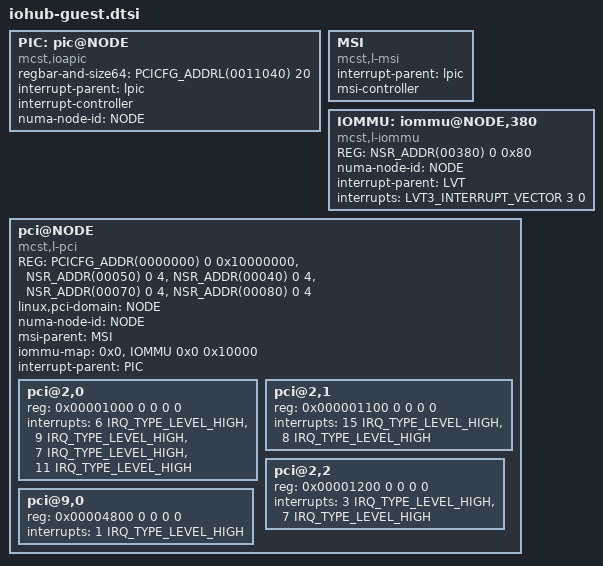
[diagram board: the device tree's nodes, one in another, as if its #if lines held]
/*
 * SPDX-License-Identifier: GPL-2.0
 * Copyright (c) 2023 MCST
 */

#ifndef CELLS
# error CELLS undefined
#endif

#if CELLS == 1
# define REG reg32
#else
# define REG reg
#endif

#define __IOMMU(_n) iommu ## _n
#define _IOMMU(_n) __IOMMU(_n)
#define IOMMU _IOMMU(NODE)

#define __MSI(_n) msi ## _n
#define _MSI(_n) __MSI(_n)
#define MSI _MSI(NODE)

#define __PCICFG_ADDRL(_a, _n) 0x2 ## _n ## _a
#define _PCICFG_ADDRL(_a, _n) __PCICFG_ADDRL(_a, _n)
#define PCICFG_ADDRL(_a) _PCICFG_ADDRL(_a, NODE)

#define __PCICFG_ADDR(_a, _n) 0x2 0x0 ## _n ## _a
#define _PCICFG_ADDR(_a, _n) __PCICFG_ADDR(_a, _n)
#define PCICFG_ADDR(_a) _PCICFG_ADDR(_a, NODE)

	PIC: pic@NODE {
		compatible = "mcst,ioapic";
		/* ioapic registers are in bus 0, dev 2, func 1, reg 40 */
		regbar-and-size64 = /bits/ 64 <PCICFG_ADDRL(0011040) 20>;

		interrupt-parent = <&lpic>;
		interrupt-controller;
		numa-node-id = <NODE>;

		#interrupt-cells = <2>;
	};
	MSI: MSI {
		compatible = "mcst,l-msi";
		interrupt-parent = <&lpic>;
		msi-controller;
	};
	IOMMU: iommu@NODE,380 {
		compatible = "mcst,l-iommu";
		REG = <NSR_ADDR(00380) 0 0x80>;

		#iommu-cells = <1>;

		numa-node-id = <NODE>;
		interrupt-parent = <&LVT>;
		interrupts = <LVT3_INTERRUPT_VECTOR 3 0>;
	};

	pci@NODE {
		compatible = "mcst,l-pci";
		REG = <PCICFG_ADDR(0000000) 0 0x10000000>, /*E2S_PCICFG_AREA_PHYS_BASE*/
			<NSR_ADDR(00050) 0 4>, /*SIC_rt_pciio0*/
			<NSR_ADDR(00040) 0 4>, /*SIC_rt_pcim0*/
			<NSR_ADDR(00070) 0 4>, /*SIC_rt_pcimp_b0*/
			<NSR_ADDR(00080) 0 4>; /*SIC_rt_pcimp_e0*/
		reg-names = "cfg", "io", "mem", "pref-bgn", "pref-end";

		linux,pci-domain = <NODE>;
		numa-node-id = <NODE>;
		msi-parent = <&MSI>;
		/*rid-base,iommu,iommu-base,length*/
		iommu-map = <0x0 &IOMMU 0x0 0x10000>;
		/* 1:1 translation, max size (48-bit) of e2k address space */
		ranges = <0 0 0 /* child address */
#if CELLS == 1
			    0   /* parent address */
#elif CELLS == 2
			    0 0 /* parent address */
#else
# error CELLS not supported
#endif
			0x10000 0>;/* child size */
		interrupt-parent = <&PIC>;

		#address-cells = <3>;
		#size-cells = <2>;

		/* reg: 00000000 00000000 dddddfff 00000000 */
		pci@2,0 { /*GPIO-MPV controller*/
			reg = <0x00001000 0 0 0 0>;
			interrupts =    < 6 IRQ_TYPE_LEVEL_HIGH>, /*Mpv_timers0*/
					< 9 IRQ_TYPE_LEVEL_HIGH>, /*Mpv_timers12*/
					< 7 IRQ_TYPE_LEVEL_HIGH>, /*GPIO0*/
					<11 IRQ_TYPE_LEVEL_HIGH>; /*GPIO1*/
			interrupt-names = "mpv0", "mpv1", "gpio0", "gpio1";
		};
		pci@2,1 { /*i2c-spi*/
			reg = <0x000001100 0 0 0 0>;
			interrupts =	<15 IRQ_TYPE_LEVEL_HIGH>, /*I2C-SPI*/
					< 8 IRQ_TYPE_LEVEL_HIGH>; /*WD Timer*/
		};
		pci@2,2 { /*Serial and Parallel ports*/
			reg = <0x00001200 0 0 0 0>;
			interrupts =	< 3 IRQ_TYPE_LEVEL_HIGH>, /*Serial Port*/
					< 7 IRQ_TYPE_LEVEL_HIGH>; /*Parallel Port*/
		};
		pci@9,0 { /*SPMC System Power Managment Controller*/
			reg = <0x00004800 0 0 0 0>;
			interrupts = <1 IRQ_TYPE_LEVEL_HIGH>;
		};
	};
